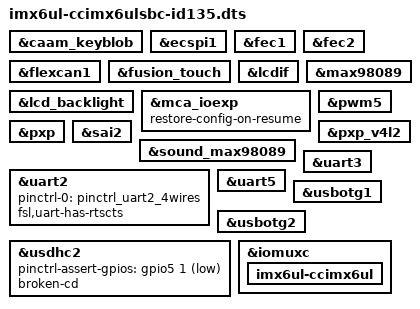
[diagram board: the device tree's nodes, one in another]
/*
 * Copyright 2016 Digi International, Inc.
 *
 * The code contained herein is licensed under the GNU General Public
 * License. You may obtain a copy of the GNU General Public License
 * Version 2 or later at the following locations:
 *
 * http://www.opensource.org/licenses/gpl-license.html
 * http://www.gnu.org/copyleft/gpl.html
 */

/dts-v1/;
#include <dt-bindings/input/input.h>
#include <dt-bindings/interrupt-controller/irq.h>
/* i.MX6 UltraLite CPU */
#include "imx6ul.dtsi"
/* ConnectCore 6UL (wireless/bluetooth variant) */
#include "imx6ul-ccimx6ul-wb.dtsi"
/* ConnectCore 6UL SBC */
#include "imx6ul-ccimx6ulsbc.dtsi"

/*
 * Uncomment to enable the i.MX6UL SoC ADCs on the GPIO connector:
 *  - EXP_GPIO_1 (channel 5)
 *  - EXP_GPIO_2 (channel 3)
 *  - EXP_GPIO_3 (channel 2)
 * Include in adc-ch-list the ADC channels (from 0 to 9) that you want to
 * enable. Note that the iomux has to be configured accordingly in pinctrl_adc1
 * to configure the pad for ADC operation
 */
//&adc1 {
//	pinctrl-names = "default";
//	pinctrl-0 = <&pinctrl_adc1>;
//	adc-ch-list = <2 3 5>;
//	status = "okay";
//};

&caam_keyblob {
	status = "okay";
};

/*
 * CSI camera conflicts with microSD/eMMC.
 * Before enabling the camera you need to disable
 * usdhc2 node.
 */
// &csi {
//	status = "okay";
// };

/* ECSPI1 */
&ecspi1 {
	/*
	 * There are no SPI slave devices on the SBC.
	 * Enable if adding your slave devices below.
	 */
	//status = "okay";

	/* Add your slave devices here. Next is an example of spidev. */
	//spidev@0 {
	//	reg = <0>;
	//	compatible = "spidev";
	//	spi-max-frequency = <1000000>;
	//};
};

/* ENET1 */
&fec1 {
	status = "okay";
};

/* ENET2 */
&fec2 {
	status = "okay";
};

/* CAN1 (multiplexed with UART3 RTS/CTS) */
&flexcan1 {
	status = "okay";
};

/* CAN2 (multiplexed with UART2 RTS/CTS) */
// &flexcan2 {
// 	status = "okay";
// };

/* Fusion touch */
&fusion_touch {
	status = "okay";
};

/* Parallel LCD */
&lcdif {
	status = "okay";
};

/* LCD backlight (PWM5) */
&lcd_backlight {
	status = "okay";
};

&max98089 {
	status = "okay";
};

/*
 * Uncomment to enable MCA ADC channels on GPIO connector:
 *  - MCA_IO1 (channel 1)
 *  - MCA_IO3 (channel 3)
 * Edit adc-ch-list to include the ADC channels that you want to enable.
 */
// &mca_adc {
// 	digi,adc-ch-list = <1 3>;
// 	digi,adc-vref = <3000000>;
// };

&mca_ioexp {
	status = "okay";
	restore-config-on-resume;
};

/*
 * Uncomment to enable the I/O Expander ADCs on GPIO connector:
 *  - IOEXP_3 (channel 3)
 *  - IOEXP_4 (channel 4)
 *  - IOEXP_5 (channel 5)
 * Include in adc-ch-list the ADC channels that you want to enable.
 */
// &mca_ioexp_adc {
// 	digi,adc-ch-list = <3 4 5>;
// 	digi,adc-vref = <3300000>;
// };

/* Uncomment to Enable Tamper detection. There are 2 digital (0 and 1) and 2
 * analog (2 and 3) tamper interfaces.
 */
//&mca_tamper {
//	digi,tamper-if-list = <0 1 2 3>;
//};

/*
 * CSI camera conflicts with microSD/eMMC.
 * Before enabling the camera you need to disable
 * usdhc2 node.
 */
// &ov5642 {
//	status = "okay";
// };

&pwm5 {
	status = "okay";
};

&pxp {
	status = "okay";
};

&pxp_v4l2 {
	status = "okay";
};

&sai2 {
	status = "okay";
};

&sound_max98089 {
	status = "okay";
};

/* UART2 */
&uart2 {
	/* RTS/CTS lines multiplexed with CAN2 */
	pinctrl-0 = <&pinctrl_uart2_4wires>;
	fsl,uart-has-rtscts;
	status = "okay";
};

/* UART3 */
&uart3 {
	/* RTS/CTS lines multiplexed with CAN1 */
	// pinctrl-0 = <&pinctrl_uart3_4wires>;
	// fsl,uart-has-rtscts;
	status = "okay";
};

/* UART5 (Console) */
&uart5 {
	status = "okay";
};

&usbotg1 {
	status = "okay";
};

&usbotg2 {
	status = "okay";
};

/* USDHC2 (microSD, conflicts with eMMC) */
&usdhc2 {
	pinctrl-assert-gpios = <&gpio5 1 GPIO_ACTIVE_LOW>;
	broken-cd;	/* no carrier detect line (use polling) */
	status = "okay";
};

/* USDHC2 (eMMC, conflicts with microSD) */
//&usdhc2 {
//	pinctrl-assert-gpios = <&gpio5 1 GPIO_ACTIVE_HIGH>;
//	non-removable;
//	/*
//	 * Comment these two lines for 4-bit data bus or leave uncommented
//	 * for 8-bit data bus
//	 */
//	pinctrl-0 = <&pinctrl_usdhc2_8databits>;
//	bus-width = <8>;
//
//	status = "okay";
//};

/* Pin mux configuration */
&iomuxc {
	imx6ul-ccimx6ul {
		/* Uncomment specific pins of the ADC channels enabled in 'adc-ch-list' */
		//pinctrl_adc1: adc1grp {
		//	fsl,pins = <
		//		/* EXP_GPIO_1 -> GPIO1_5/ADC1_IN5 */
		//		MX6UL_PAD_GPIO1_IO05__GPIO1_IO05        0xb0
		//		/* EXP_GPIO_2 -> GPIO1_3/ADC1_IN3 */
		//		MX6UL_PAD_GPIO1_IO03__GPIO1_IO03        0xb0
		//		/* EXP_GPIO_3 -> GPIO1_2/ADC1_IN2 */
		//		MX6UL_PAD_GPIO1_IO02__GPIO1_IO02        0xb0
		//	>;
		//};
	};
};
